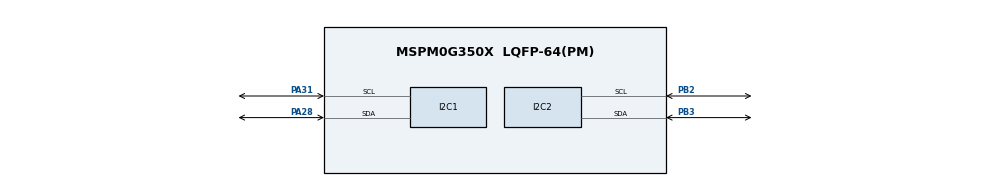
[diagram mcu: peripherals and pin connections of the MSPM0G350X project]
/**
 * @cliArgs --device "MSPM0G350X" --part "Default" --package "LQFP-64(PM)" --product "mspm0_sdk@2.04.00.06"
 * @versions {"tool":"1.23.0+4000"}
 */

/**
 * Import the modules used in this configuration.
 */
const GPIO    = scripting.addModule("/ti/driverlib/GPIO", {}, false);
const GPIO1   = GPIO.addInstance();
const I2C     = scripting.addModule("/ti/driverlib/I2C", {}, false);
const I2C1    = I2C.addInstance();
const I2C2    = I2C.addInstance();
const SYSCTL  = scripting.addModule("/ti/driverlib/SYSCTL");
const SYSTICK = scripting.addModule("/ti/driverlib/SYSTICK");

/**
 * Write custom configuration values to the imported modules.
 */
const divider7       = system.clockTree["PLL_PDIV"];
divider7.divideValue = 2;

const divider9       = system.clockTree["UDIV"];
divider9.divideValue = 2;

const multiplier2         = system.clockTree["PLL_QDIV"];
multiplier2.multiplyValue = 5;

const mux8       = system.clockTree["HSCLKMUX"];
mux8.inputSelect = "HSCLKMUX_SYSPLL2X";

GPIO1.$name                                 = "GPIO_MPU6050";
GPIO1.associatedPins[0].$name               = "PIN_INT";
GPIO1.associatedPins[0].direction           = "INPUT";
GPIO1.associatedPins[0].assignedPort        = "PORTB";
GPIO1.associatedPins[0].assignedPin         = "1";
GPIO1.associatedPins[0].assignedPortSegment = "Lower";
GPIO1.associatedPins[0].interruptEn         = true;
GPIO1.associatedPins[0].polarity            = "RISE";

const Board = scripting.addModule("/ti/driverlib/Board", {}, false);

I2C1.$name                             = "I2C_MPU6050";
I2C1.basicEnableController             = true;
I2C1.basicControllerStandardBusSpeed   = "Fast";
I2C1.advAnalogGlitchFilter             = "5";
I2C1.advControllerClkStretch           = false;
I2C1.peripheral.$assign                = "I2C0";
I2C1.peripheral.sdaPin.$assign         = "PA28";
I2C1.peripheral.sclPin.$assign         = "PA31";
I2C1.sdaPinConfig.$name                = "ti_driverlib_gpio_GPIOPinGeneric0";
I2C1.sdaPinConfig.hideOutputInversion  = scripting.forceWrite(false);
I2C1.sdaPinConfig.onlyInternalResistor = scripting.forceWrite(false);
I2C1.sdaPinConfig.passedPeripheralType = scripting.forceWrite("Digital");
I2C1.sclPinConfig.$name                = "ti_driverlib_gpio_GPIOPinGeneric1";
I2C1.sclPinConfig.hideOutputInversion  = scripting.forceWrite(false);
I2C1.sclPinConfig.onlyInternalResistor = scripting.forceWrite(false);
I2C1.sclPinConfig.passedPeripheralType = scripting.forceWrite("Digital");

I2C2.$name                             = "I2C_OLED";
I2C2.basicEnableController             = true;
I2C2.basicControllerStandardBusSpeed   = "Fast";
I2C2.peripheral.$assign                = "I2C1";
I2C2.peripheral.sdaPin.$assign         = "PB3";
I2C2.peripheral.sclPin.$assign         = "PB2";
I2C2.sdaPinConfig.$name                = "ti_driverlib_gpio_GPIOPinGeneric2";
I2C2.sdaPinConfig.hideOutputInversion  = scripting.forceWrite(false);
I2C2.sdaPinConfig.onlyInternalResistor = scripting.forceWrite(false);
I2C2.sdaPinConfig.passedPeripheralType = scripting.forceWrite("Digital");
I2C2.sclPinConfig.$name                = "ti_driverlib_gpio_GPIOPinGeneric3";
I2C2.sclPinConfig.hideOutputInversion  = scripting.forceWrite(false);
I2C2.sclPinConfig.onlyInternalResistor = scripting.forceWrite(false);
I2C2.sclPinConfig.passedPeripheralType = scripting.forceWrite("Digital");

SYSCTL.forceDefaultClkConfig = true;

SYSTICK.periodEnable    = true;
SYSTICK.period          = 32000;
SYSTICK.systickEnable   = true;
SYSTICK.interruptEnable = true;

/**
 * Pinmux solution for unlocked pins/peripherals. This ensures that minor changes to the automatic solver in a future
 * version of the tool will not impact the pinmux you originally saw.  These lines can be completely deleted in order to
 * re-solve from scratch.
 */
GPIO1.associatedPins[0].pin.$suggestSolution = "PB1";
Board.peripheral.$suggestSolution            = "DEBUGSS";
Board.peripheral.swclkPin.$suggestSolution   = "PA20";
Board.peripheral.swdioPin.$suggestSolution   = "PA19";
SYSCTL.peripheral.$suggestSolution           = "SYSCTL";
